# APM32F107xx register map
File version: 1.0
CPU: CM3 r2p1, little endian, no MPU, no FPU, 4 interrupt priority bits
Registers are 32-bit, read-write, reset 0x0 unless marked. A register's access mark holds for its fields unless they carry their own. Offsets are from the block's base; [hi:lo] are bit positions; {n}, {i} and the like mark numbered series.

## SPI1 — Serial peripheral interface
Base 0x40013000
Same registers: SPI2 0x40003800, SPI3 0x40003C00
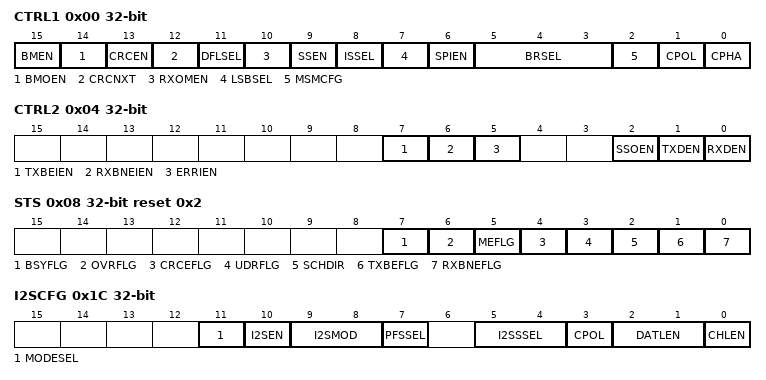
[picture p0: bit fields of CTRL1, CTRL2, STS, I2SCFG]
0x00 CTRL1 — control register 1
  [15] BMEN — Bidirectional data mode enable
  [14] BMOEN — Output enable in bidirectional mode
  [13] CRCEN — Hardware CRC calculation enable
  [12] CRCNXT — CRC transfer next
  [11] DFLSEL — Data frame format
  [10] RXOMEN — Receive only
  [9] SSEN — Software slave management
  [8] ISSEL — Internal slave select
  [7] LSBSEL — Frame format
  [6] SPIEN — SPI enable
  [5:3] BRSEL — Baud rate control
  [2] MSMCFG — Master selection
  [1] CPOL — Clock polarity
  [0] CPHA — Clock phase
0x04 CTRL2 — control register 2
  [7] TXBEIEN — Tx buffer empty interrupt enable
  [6] RXBNEIEN — RX buffer not empty interrupt enable
  [5] ERRIEN — Error interrupt enable
  [2] SSOEN — SS output enable
  [1] TXDEN — Tx buffer DMA enable
  [0] RXDEN — Rx buffer DMA enable
0x08 STS access per field reset 0x2 — status register
  [7] BSYFLG ro — Busy flag
  [6] OVRFLG ro — Overrun flag
  [5] MEFLG ro — Mode fault
  [4] CRCEFLG rw — CRC error flag
  [3] UDRFLG ro — Underrun flag
  [2] SCHDIR ro — Channel side
  [1] TXBEFLG ro — Transmit buffer empty
  [0] RXBNEFLG ro — Receive buffer not empty
0x0C DATA
  [15:0] DATA
0x10 CRCPOLY reset 0x7 — CRC polynomial register
  [15:0] CRCPOLY
0x14 RXCRC ro
  [15:0] RXCRC
0x18 TXCRC ro
  [15:0] TXCRC
0x1C I2SCFG — I2S configuration register
  [11] MODESEL — I2S mode selection
  [10] I2SEN — I2S Enable
  [9:8] I2SMOD — I2S configuration mode
  [7] PFSSEL — PCM frame synchronization
  [5:4] I2SSSEL — I2S standard selection
  [3] CPOL — Steady state clock polarity
  [2:1] DATLEN — Data length to be transferred
  [0] CHLEN — Channel length (number of bits per audio channel)
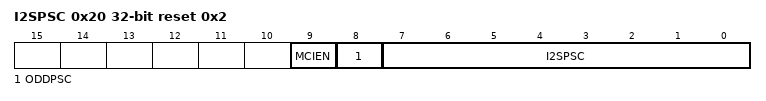
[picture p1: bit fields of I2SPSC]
0x20 I2SPSC reset 0x2 — I2S prescaler register
  [9] MCIEN — Master clock output enable
  [8] ODDPSC — Odd factor for the prescaler
  [7:0] I2SPSC — I2S Linear prescaler

## TMR6 — Advanced timer
Base 0x40001000
Same registers: TMR7 0x40001400
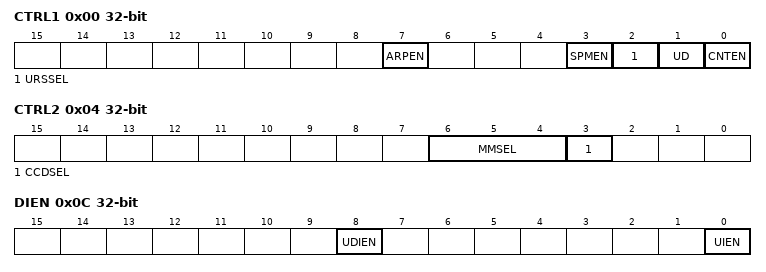
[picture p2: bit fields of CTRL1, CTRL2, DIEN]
0x00 CTRL1 — control register 1
  [7] ARPEN — Auto-reload preload enable
  [3] SPMEN — One-pulse mode
  [2] URSSEL — Update request source
  [1] UD — Update disable
  [0] CNTEN — Counter enable
0x04 CTRL2 — control register 2
  [6:4] MMSEL — Master mode selection
  [3] CCDSEL — Capture/compare DMA selection
0x0C DIEN — DMA/Interrupt enable register
  [8] UDIEN — Update DMA request enable
  [0] UIEN — Update interrupt enable
0x10 STS — status register
  [0] UIFLG — Update interrupt flag
0x14 CEG wo — event generation register
  [0] UEG — Update generation
0x24 CNT — counter
  [15:0] CNT — counter value
0x28 PSC — prescaler
  [15:0] PSC — Prescaler value
0x2C AUTORLD — auto-reload register
  [15:0] AUTORLD — Auto-reload value

## NVIC — Nested Vectored Interrupt Controller
Base 0xE000E000
0x04 ICTR ro — Interrupt Controller Type Register
  [3:0] INTLINESNUM — Total number of interrupt lines in groups
0x100 ISER0 — Interrupt Set-Enable Register
  [31:0] SETENA
0x104 ISER1 — Interrupt Set-Enable Register
  [31:0] SETENA
0x180 ICER0 — Interrupt Clear-Enable Register
  [31:0] CLRENA
0x184 ICER1 — Interrupt Clear-Enable Register
  [31:0] CLRENA
0x200 ISPR0 — Interrupt Set-Pending Register
  [31:0] SETPEND
0x204 ISPR1 — Interrupt Set-Pending Register
  [31:0] SETPEND
0x280 ICPR0 — Interrupt Clear-Pending Register
  [31:0] CLRPEND
0x284 ICPR1 — Interrupt Clear-Pending Register
  [31:0] CLRPEND
0x300 IABR0 ro — Interrupt Active Bit Register
  [31:0] ACTIVE
0x304 IABR1 ro — Interrupt Active Bit Register
  [31:0] ACTIVE
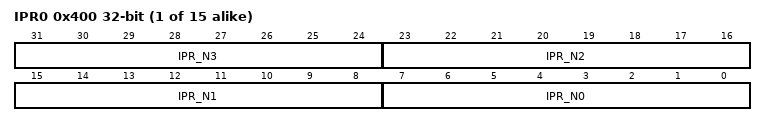
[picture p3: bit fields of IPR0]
{0x400+4i} IPR{i} (i=0..14) — Interrupt Priority Register
  [8n+7:8n] IPR_N{n} (n=0..3)
0xF00 STIR wo — Software Triggered Interrupt Register
  [8:0] INTID — interrupt to be triggered
